AUTOSAR XML (schema 4-2-2)
package /AUTOSAR_Det/SwComponentTypes
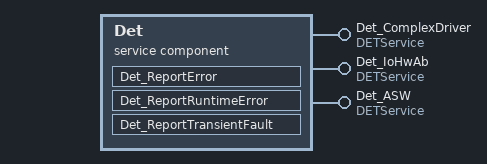
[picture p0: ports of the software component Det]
  service sw component type Det
    provide port Det_ComplexDriver: provided-interface=DETService
      provided-com-specs:
        operation=ReportError, queue-length=1
        operation=ReportRuntimeError, queue-length=1
        operation=ReportTransientFault, queue-length=1
    provide port Det_IoHwAb: provided-interface=DETService
      provided-com-specs:
        operation=ReportError, queue-length=1
        operation=ReportRuntimeError, queue-length=1
        operation=ReportTransientFault, queue-length=1
    provide port Det_ASW: provided-interface=DETService
      provided-com-specs:
        operation=ReportError, queue-length=1
        operation=ReportRuntimeError, queue-length=1
        operation=ReportTransientFault, queue-length=1
    behavior IntBeh_Det
      9 x operation invoked event:
        OpInvEvent_DETServices_ReportError_ComplexDriver: start-on-event=Det_ReportError, operation=Det_ComplexDriver.ReportError
        OpInvEvent_DETServices_ReportRuntimeError_ComplexDriver: start-on-event=Det_ReportRuntimeError, operation=Det_ComplexDriver.ReportRuntimeError
        OpInvEvent_DETServices_ReportTransientFault_ComplexDriver: start-on-event=Det_ReportTransientFault, operation=Det_ComplexDriver.ReportTransientFault
        OpInvEvent_DETServices_ReportError_IoHwAb: start-on-event=Det_ReportError, operation=Det_IoHwAb.ReportError
        OpInvEvent_DETServices_ReportRuntimeError_IoHwAb: start-on-event=Det_ReportRuntimeError, operation=Det_IoHwAb.ReportRuntimeError
        OpInvEvent_DETServices_ReportTransientFault_IoHwAb: start-on-event=Det_ReportTransientFault, operation=Det_IoHwAb.ReportTransientFault
        OpInvEvent_DETServices_ReportError_ASW: start-on-event=Det_ReportError, operation=Det_ASW.ReportError
        OpInvEvent_DETServices_ReportRuntimeError_ASW: start-on-event=Det_ReportRuntimeError, operation=Det_ASW.ReportRuntimeError
        OpInvEvent_DETServices_ReportTransientFault_ASW: start-on-event=Det_ReportTransientFault, operation=Det_ASW.ReportTransientFault
      port-api-options:
        {enable-take-address=false, indirect-api=false, port-defined-argument-value{value=Det_ComplexDriver:4096, value-type=uint16}, port=Det_ComplexDriver}
        {enable-take-address=false, indirect-api=false, port-defined-argument-value{value=Det_IoHwAb:4097, value-type=uint16}, port=Det_IoHwAb}
        {enable-take-address=false, indirect-api=false, port-defined-argument-value{value=Det_ASW:4098, value-type=uint16}, port=Det_ASW}
      runnable Det_ReportError: arguments=[symbol=ModuleId, symbol=InstanceId, symbol=ApiId, symbol=ErrorId], can-be-invoked-concurrently=true
      runnable Det_ReportRuntimeError: arguments=[symbol=ModuleId, symbol=InstanceId, symbol=ApiId, symbol=ErrorId], can-be-invoked-concurrently=true
      runnable Det_ReportTransientFault: arguments=[symbol=ModuleId, symbol=InstanceId, symbol=ApiId, symbol=FaultId], can-be-invoked-concurrently=true
package /AUTOSAR_Det/SwcImplementations
  swc implementation Impl_Det: programming-language=C, sw-version=9.0.0, vendor-id=6, behavior=IntBeh_Det
    code-descriptors:
      code CodeDescr_Det: artifact-descriptors=autosar-engineering-object={short-label=Code_0, category=SWSRC}
    resource consumption Det_ResourceConsumption
      5 x memory section:
        DET_VAR_CLEARED: prefix=DET, sw-addrmethod=VAR_CLEARED, symbol=VAR_CLEARED
        DET_VAR_INIT_UNSPECIFIED: prefix=DET, sw-addrmethod=VAR_INIT, symbol=VAR_INIT_UNSPECIFIED
        DET_CONST_UNSPECIFIED: prefix=DET, sw-addrmethod=CONST, symbol=CONST_UNSPECIFIED
        DET_CODE: prefix=DET, sw-addrmethod=CODE, symbol=CODE
        Det_CODE: prefix=Det, sw-addrmethod=CODE, symbol=CODE
      section name prefix DET
      section name prefix Det
package /AUTOSAR_Det/PortInterfaces
  client server interface DETService: is-service=true
    operation ReportError: possible-error=E_OK
      arg InstanceId: type=uint8, direction=IN
      arg ApiId: type=uint8, direction=IN
      arg ErrorId: type=uint8, direction=IN
    operation ReportRuntimeError: possible-error=E_OK
      arg InstanceId: type=uint8, direction=IN
      arg ApiId: type=uint8, direction=IN
      arg ErrorId: type=uint8, direction=IN
    operation ReportTransientFault: possible-error=E_OK
      arg InstanceId: type=uint8, direction=IN
      arg ApiId: type=uint8, direction=IN
      arg FaultId: type=uint8, direction=IN
    error E_OK: error-code=0
